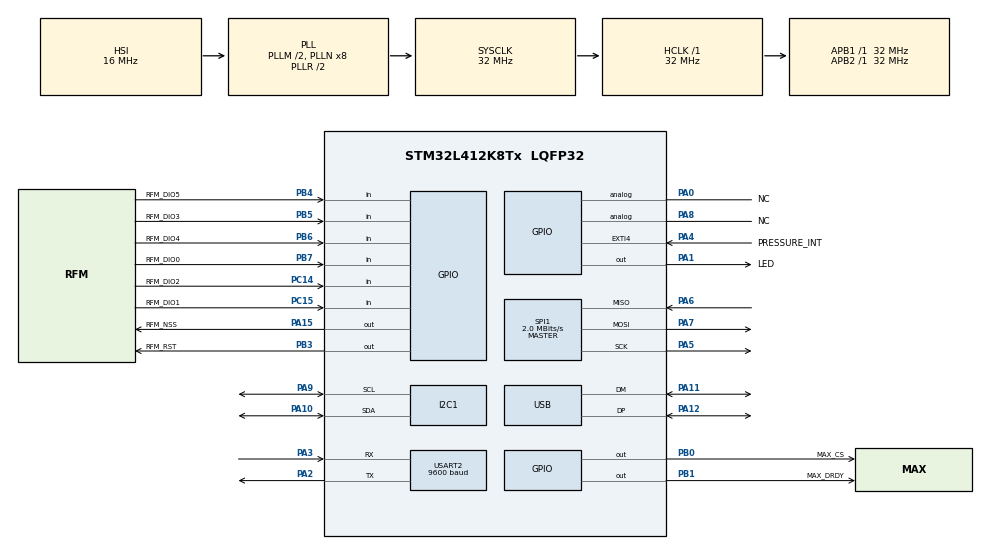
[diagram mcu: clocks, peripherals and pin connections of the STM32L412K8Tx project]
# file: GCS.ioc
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I2C1.Timing=0x00707CBB
Mcu.Family=STM32L4
Mcu.Name=STM32L412K8Tx
Mcu.Package=LQFP32
NVIC.PriorityGroup=NVIC_PRIORITYGROUP_4
NVIC.USART2_IRQn=true\:0\:0\:false\:false\:true\:true\:true
NVIC.USB_IRQn=true\:0\:0\:false\:false\:true\:false\:true
PA0-CK_IN.GPIO_Label=NC
PA0-CK_IN.Signal=GPIO_Analog
PA1.GPIO_Label=LED
PA1.Signal=GPIO_Output
PA10.Mode=I2C
PA10.Signal=I2C1_SDA
PA11.Mode=Device
PA11.Signal=USB_DM
PA12.Mode=Device
PA12.Signal=USB_DP
PA13\ (JTMS/SWDIO).Mode=Serial_Wire
PA13\ (JTMS/SWDIO).Signal=SYS_JTMS-SWDIO
PA14\ (JTCK/SWCLK).Mode=Serial_Wire
PA14\ (JTCK/SWCLK).Signal=SYS_JTCK-SWCLK
PA15\ (JTDI).GPIO_Label=RFM_NSS
PA15\ (JTDI).Signal=GPIO_Output
PA2.Mode=Asynchronous
PA2.Signal=USART2_TX
PA3.Mode=Asynchronous
PA3.Signal=USART2_RX
PA4.GPIO_Label=PRESSURE_INT
PA4.Signal=GPXTI4
PA5.Mode=Full_Duplex_Master
PA5.Signal=SPI1_SCK
PA6.Mode=Full_Duplex_Master
PA6.Signal=SPI1_MISO
PA7.Mode=Full_Duplex_Master
PA7.Signal=SPI1_MOSI
PA8.GPIO_Label=NC
PA8.Signal=GPIO_Analog
PA9.Mode=I2C
PA9.Signal=I2C1_SCL
PB0.GPIO_Label=MAX_CS
PB0.Signal=GPIO_Output
PB1.GPIO_Label=MAX_DRDY
PB1.Signal=GPIO_Output
PB3\ (JTDO/TRACESWO).GPIO_Label=RFM_RST
PB3\ (JTDO/TRACESWO).Signal=GPIO_Output
PB4\ (NJTRST).GPIO_Label=RFM_DIO5
PB4\ (NJTRST).Signal=GPIO_Input
PB5.GPIO_Label=RFM_DIO3
PB5.Signal=GPIO_Input
PB6.GPIO_Label=RFM_DIO4
PB6.Signal=GPIO_Input
PB7.GPIO_Label=RFM_DIO0
PB7.Signal=GPIO_Input
PC14-OSC32_IN\ (PC14).GPIO_Label=RFM_DIO2
PC14-OSC32_IN\ (PC14).Signal=GPIO_Input
PC15-OSC32_OUT\ (PC15).GPIO_Label=RFM_DIO1
PC15-OSC32_OUT\ (PC15).Signal=GPIO_Input
ProjectManager.HeapSize=0x200
ProjectManager.StackSize=0x400
ProjectManager.TargetToolchain=STM32CubeIDE
RCC.ADCFreq_Value=32000000
RCC.AHBFreq_Value=32000000
RCC.APB1Freq_Value=32000000
RCC.APB1TimFreq_Value=32000000
RCC.APB2Freq_Value=32000000
RCC.APB2TimFreq_Value=32000000
RCC.CK48CLockSelection=RCC_USBCLKSOURCE_HSI48
RCC.CortexFreq_Value=32000000
RCC.HCLKFreq_Value=32000000
RCC.HSE_VALUE=8000000
RCC.HSI48_VALUE=48000000
RCC.HSI_VALUE=16000000
RCC.LSE_VALUE=32768
RCC.MSIClockRange=RCC_MSIRANGE_9
RCC.MSI_VALUE=24000000
RCC.PLLM=2
RCC.PLLSourceVirtual=RCC_PLLSOURCE_HSI
RCC.SYSCLKFreq_VALUE=32000000
RCC.SYSCLKSource=RCC_SYSCLKSOURCE_PLLCLK
RCC.USBFreq_Value=48000000
RCC.VCOOutputFreq_Value=64000000
SPI1.BaudRatePrescaler=SPI_BAUDRATEPRESCALER_16
SPI1.CalculateBaudRate=2.0 MBits/s
SPI1.DataSize=SPI_DATASIZE_8BIT
SPI1.Direction=SPI_DIRECTION_2LINES
SPI1.Mode=SPI_MODE_MASTER
SPI1.VirtualType=VM_MASTER
USART2.BaudRate=9600
USART2.Mode=MODE_RX
USART2.VirtualMode-Asynchronous=VM_ASYNC
USB_DEVICE.CLASS_NAME_FS=CDC
USB_DEVICE.VirtualMode=Cdc
USB_DEVICE.VirtualModeFS=Cdc_FS
VP_USB_DEVICE_VS_USB_DEVICE_CDC_FS.Mode=CDC_FS
board=custom

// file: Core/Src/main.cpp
/* USER CODE BEGIN Header */
/**
  ******************************************************************************
  * @file           : main.c
  * @brief          : Main program body
  ******************************************************************************
  * @attention
  *
  * <h2><center>&copy; Copyright (c) 2020 STMicroelectronics.
  * All rights reserved.</center></h2>
  *
  * This software component is licensed by ST under BSD 3-Clause license,
  * the "License"; You may not use this file except in compliance with the
  * License. You may obtain a copy of the License at:
  *                        opensource.org/licenses/BSD-3-Clause
  *
  ******************************************************************************
  */
/* USER CODE END Header */

#include "main.h"
#include "i2c.h"
#include "spi.h"
#include "usart.h"
#include "usb_device.h"
#include "gpio.h"

/* USER CODE BEGIN Includes */
#include "AppMain/AppMain.h"
/* USER CODE END Includes */

/* USER CODE BEGIN PTD */
AppMain appMain;
/* USER CODE END PTD */

/* USER CODE BEGIN PM */

extern UART_HandleTypeDef huart2;
/* USER CODE END PM */

void SystemClock_Config(void);

/* USER CODE BEGIN 0 */
uint8_t rxData[1] = {0};
/* USER CODE END 0 */

int main(void)
{

  /* MCU Configuration--------------------------------------------------------*/

  /* Reset of all peripherals, Initializes the Flash interface and the Systick. */
  HAL_Init();

  /* Configure the system clock */
  SystemClock_Config();

  /* Initialize all configured peripherals */
  MX_GPIO_Init();
  MX_I2C1_Init();
  MX_SPI1_Init();
  MX_USART2_UART_Init();
  MX_USB_DEVICE_Init();
  /* USER CODE BEGIN 2 */

  HAL_UART_MspInit(&huart2);		//UART init
  HAL_SPI_MspInit(&hspi1);		//SPI init
  HAL_UART_Receive_IT(&huart2, rxData, 1);
  appMain.mainProg();
  /* USER CODE END 2 */

  /* Infinite loop */
  while (1)
  {

  }
}

void SystemClock_Config(void)
{
  RCC_OscInitTypeDef RCC_OscInitStruct = {0};
  RCC_ClkInitTypeDef RCC_ClkInitStruct = {0};
  RCC_PeriphCLKInitTypeDef PeriphClkInit = {0};

  /** Configure the main internal regulator output voltage
  */
  if (HAL_PWREx_ControlVoltageScaling(PWR_REGULATOR_VOLTAGE_SCALE1) != HAL_OK)
  {
    Error_Handler();
  }
  /** Initializes the CPU, AHB and APB busses clocks
  */
  RCC_OscInitStruct.OscillatorType = RCC_OSCILLATORTYPE_HSI48|RCC_OSCILLATORTYPE_HSI;
  RCC_OscInitStruct.HSIState = RCC_HSI_ON;
  RCC_OscInitStruct.HSI48State = RCC_HSI48_ON;
  RCC_OscInitStruct.HSICalibrationValue = RCC_HSICALIBRATION_DEFAULT;
  RCC_OscInitStruct.PLL.PLLState = RCC_PLL_ON;
  RCC_OscInitStruct.PLL.PLLSource = RCC_PLLSOURCE_HSI;
  RCC_OscInitStruct.PLL.PLLM = 2;
  RCC_OscInitStruct.PLL.PLLN = 8;
  RCC_OscInitStruct.PLL.PLLQ = RCC_PLLQ_DIV2;
  RCC_OscInitStruct.PLL.PLLR = RCC_PLLR_DIV2;
  if (HAL_RCC_OscConfig(&RCC_OscInitStruct) != HAL_OK)
  {
    Error_Handler();
  }
  /** Initializes the CPU, AHB and APB busses clocks
  */
  RCC_ClkInitStruct.ClockType = RCC_CLOCKTYPE_HCLK|RCC_CLOCKTYPE_SYSCLK
                              |RCC_CLOCKTYPE_PCLK1|RCC_CLOCKTYPE_PCLK2;
  RCC_ClkInitStruct.SYSCLKSource = RCC_SYSCLKSOURCE_PLLCLK;
  RCC_ClkInitStruct.AHBCLKDivider = RCC_SYSCLK_DIV1;
  RCC_ClkInitStruct.APB1CLKDivider = RCC_HCLK_DIV1;
  RCC_ClkInitStruct.APB2CLKDivider = RCC_HCLK_DIV1;

  if (HAL_RCC_ClockConfig(&RCC_ClkInitStruct, FLASH_LATENCY_1) != HAL_OK)
  {
    Error_Handler();
  }
  PeriphClkInit.PeriphClockSelection = RCC_PERIPHCLK_USART2|RCC_PERIPHCLK_I2C1
                              |RCC_PERIPHCLK_USB;
  PeriphClkInit.Usart2ClockSelection = RCC_USART2CLKSOURCE_PCLK1;
  PeriphClkInit.I2c1ClockSelection = RCC_I2C1CLKSOURCE_PCLK1;
  PeriphClkInit.UsbClockSelection = RCC_USBCLKSOURCE_HSI48;
  if (HAL_RCCEx_PeriphCLKConfig(&PeriphClkInit) != HAL_OK)
  {
    Error_Handler();
  }
}

/* USER CODE BEGIN 4 */

/**
  * @brief  Rx Transfer completed callback.
  * @param  huart UART handle.
  * @retval None
  */
void HAL_UART_RxCpltCallback(UART_HandleTypeDef *huart)
{
  /* Prevent unused argument(s) compilation warning */
	HAL_UART_Receive_IT(&huart2, rxData, 1);
	appMain.gps.gpsInterrupt(rxData[0]);

  /* NOTE : This function should not be modified, when the callback is needed,
            the HAL_UART_RxCpltCallback can be implemented in the user file.
   */
}
/* USER CODE END 4 */

void Error_Handler(void)
{
}

/************************ (C) COPYRIGHT STMicroelectronics *****END OF FILE****/
